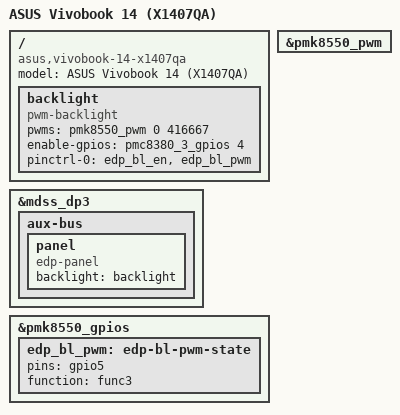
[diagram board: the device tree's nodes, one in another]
// SPDX-License-Identifier: BSD-3-Clause
/*
 * Copyright (c) 2023 Qualcomm Innovation Center, Inc. All rights reserved.
 * Copyright (c) 2025, Kellerman Rivero <krsloco@gmail.com>
 * Copyright (c) 2025 Aleksandrs Vinarskis <alex@vinarskis.com>
 *
 * ASUS Vivobook 14 (X1407QA). Its DSDT is the Vivobook 16 X1607QA's
 * apart from the SKU, the subsystem IDs and the thermal trip points,
 * so it shares that tree. It ships with a 1920x1200 IPS LCD, which the
 * DSDT gives PMIC PWM backlight, 12 bits at 2400 Hz, as on the Zenbook
 * A14 LCD, whose backlight this is.
 */

/dts-v1/;

#include "purwa.dtsi"
#include "x126100-asus-vivobook-16.dtsi"

/delete-node/ &pmc8380_6;
/delete-node/ &pmc8380_6_thermal;

/ {
	model = "ASUS Vivobook 14 (X1407QA)";
	compatible = "asus,vivobook-14-x1407qa", "qcom,x126100", "qcom,x1p42100";

	backlight: backlight {
		compatible = "pwm-backlight";
		pwms = <&pmk8550_pwm 0 416667>;
		enable-gpios = <&pmc8380_3_gpios 4 GPIO_ACTIVE_HIGH>;

		pinctrl-0 = <&edp_bl_en>, <&edp_bl_pwm>;
		pinctrl-names = "default";
	};
};

&mdss_dp3 {
	aux-bus {
		panel {
			compatible = "edp-panel";
			/delete-property/ enable-gpios;
			/delete-property/ pinctrl-0;
			/delete-property/ pinctrl-names;

			backlight = <&backlight>;
		};
	};
};

&pmk8550_gpios {
	edp_bl_pwm: edp-bl-pwm-state {
		pins = "gpio5";
		function = "func3";
	};
};

&pmk8550_pwm {
	status = "okay";
};
